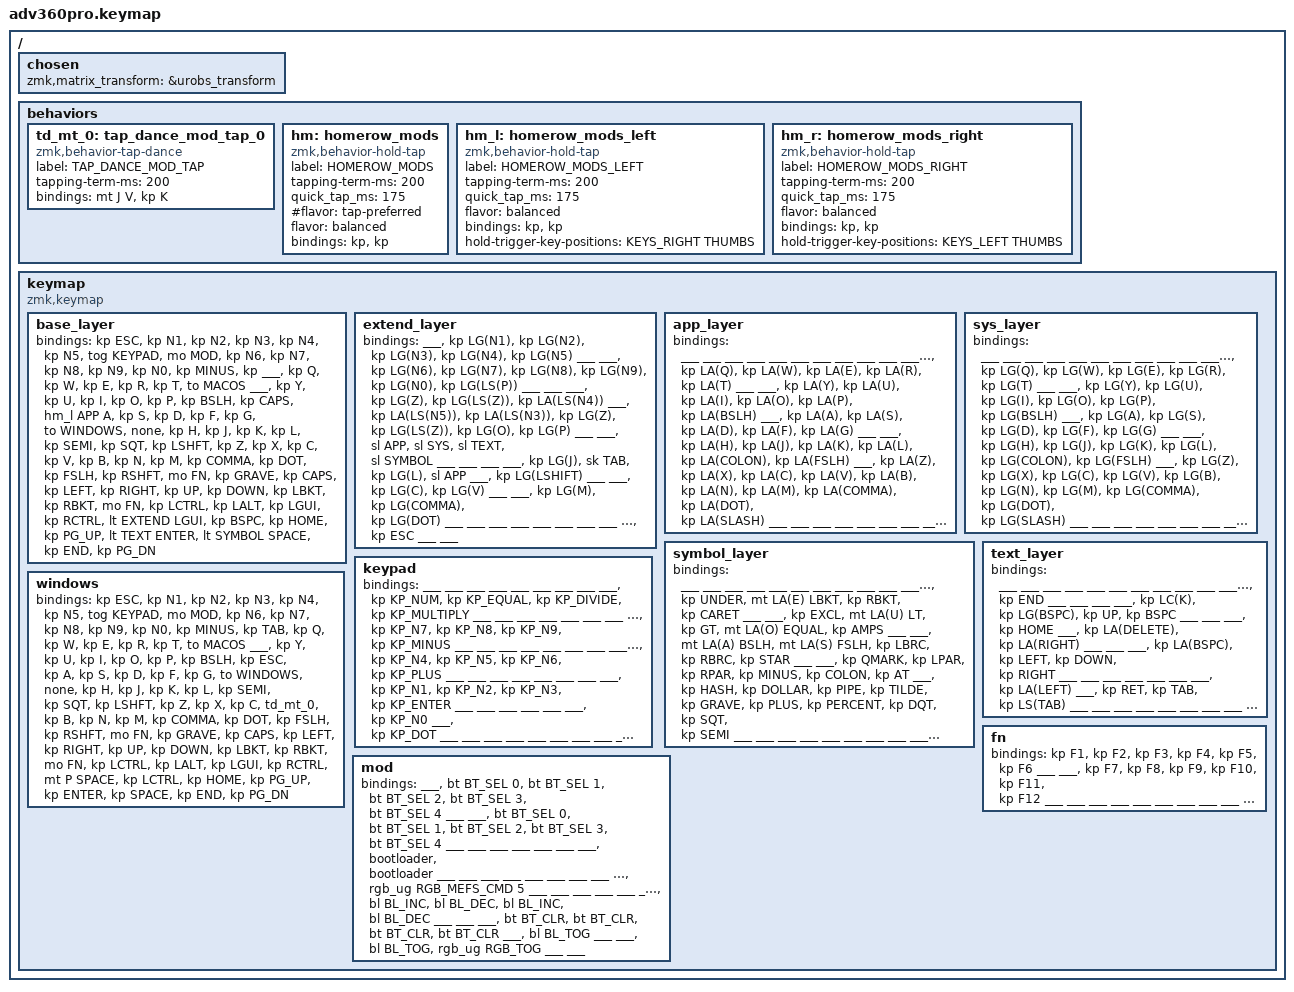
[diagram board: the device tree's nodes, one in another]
#include <behaviors.dtsi>
#include <dt-bindings/zmk/keys.h>
#include <dt-bindings/zmk/bt.h>
#include <dt-bindings/zmk/outputs.h>
#include <dt-bindings/zmk/rgb.h>
#include <dt-bindings/zmk/backlight.h>

#define ___ &trans

#define MACOS 0
#define EXTEND 1
#define APP 2
#define SYS 3
#define SYMBOL 4
#define TEXT 5
#define WINDOWS 6
#define KEYPAD 7
#define FN 8
#define MOD 9

/ {
    /* remove unused keys from layout and move thumb cluster to bottom */
    chosen {
        zmk,matrix_transform = &urobs_transform;
    };

    behaviors {
        td_mt_0: tap_dance_mod_tap_0 {
            compatible = "zmk,behavior-tap-dance";
            label = "TAP_DANCE_MOD_TAP";
            #binding-cells = <0>;
            tapping-term-ms = <200>;
            bindings = <&mt J V>, <&kp K>;
        };

	hm: homerow_mods {
        	compatible = "zmk,behavior-hold-tap";
        	label = "HOMEROW_MODS";
        	#binding-cells = <2>;
        	tapping-term-ms = <200>;
        	quick_tap_ms = <175>;
        	#flavor = "tap-preferred";
        	flavor = "balanced";
        	bindings = <&kp>, <&kp>;
    	};

	hm_l: homerow_mods_left {
        	compatible = "zmk,behavior-hold-tap";
        	label = "HOMEROW_MODS_LEFT";
        	#binding-cells = <2>;
        	tapping-term-ms = <200>;
        	quick_tap_ms = <175>;
        	flavor = "balanced";
        	bindings = <&kp>, <&kp>;
        	hold-trigger-key-positions = <KEYS_RIGHT THUMBS>;
    	};

    	hm_r: homerow_mods_right {
        	compatible = "zmk,behavior-hold-tap";
        	label = "HOMEROW_MODS_RIGHT";
        	#binding-cells = <2>;
        	tapping-term-ms = <200>;
        	quick_tap_ms = <175>;
        	flavor = "balanced";
        	bindings = <&kp>, <&kp>;
        	hold-trigger-key-positions = <KEYS_LEFT THUMBS>;
    	};
    };

    keymap {
	#include "macros.dtsi"

        compatible = "zmk,keymap";

        base_layer {
            bindings = <
                &kp ESC &kp N1    &kp N2    &kp N3    &kp N4    &kp N5    &tog KEYPAD    &mo MOD   &kp N6    &kp N7    &kp N8    &kp N9    &kp N0    &kp MINUS
                &kp ___ &kp Q     &kp W     &kp E     &kp R     &kp T     &to MACOS    ___       &kp Y     &kp U     &kp I     &kp O     &kp P     &kp BSLH
                &kp CAPS  &hm_l APP A     &kp S     &kp D     &kp F     &kp G     &to WINDOWS    &none     &kp H     &kp J     &kp K     &kp L     &kp SEMI  &kp SQT
                &kp LSHFT &kp Z     &kp X     &kp C     &kp V     &kp B                              &kp N     &kp M     &kp COMMA &kp DOT   &kp FSLH  &kp RSHFT
                &mo FN    &kp GRAVE &kp CAPS  &kp LEFT  &kp RIGHT                                              &kp UP    &kp DOWN  &kp LBKT  &kp RBKT  &mo FN
                                                                  &kp LCTRL &kp LALT       &kp LGUI  &kp RCTRL
                                                  &lt EXTEND LGUI &kp BSPC &kp HOME       &kp PG_UP &lt TEXT ENTER &lt SYMBOL SPACE
                                                                            &kp END        &kp PG_DN
            >;
        };

        extend_layer {
            bindings = <
                ___    &kp LG(N1)  &kp LG(N2)  &kp LG(N3)  &kp LG(N4)  &kp LG(N5)   ___            ___      &kp LG(N6)  &kp LG(N7)  &kp LG(N8)  &kp LG(N9)  &kp LG(N0)   &kp LG(LS(P)) 
                ___       ___       ___   &kp LG(Z) &kp LG(LS(Z))  &kp LA(LS(N4))       ___            &kp LA(LS(N5))  &kp LA(LS(N3))    &kp LG(Z) &kp LG(LS(Z))  &kp LG(O)     &kp LG(P)   ___
                ___       &sl APP   &sl SYS  &sl TEXT  &sl SYMBOL   ___       ___            ___       ___     &kp LG(J)     &sk TAB     &kp LG(L)     &sl APP    ___ 
                &kp LG(LSHIFT) ___     ___     &kp LG(C)     &kp LG(V)     ___                              ___     &kp LG(M)     &kp LG(COMMA) &kp LG(DOT)   ___  ___
                ___       ___       ___       ___       ___                                                    ___       ___       ___       ___       ___
                                                                  ___       ___            ___       ___
                                                        ___       ___       ___            ___       ___       &kp ESC
                                                                            ___            ___
            >;
        };

	app_layer {
            bindings = <
                ___       ___       ___       ___       ___       ___       ___            ___       ___       ___       ___       ___       ___       ___
                ___       &kp LA(Q)     &kp LA(W)    &kp LA(E)     &kp LA(R)     &kp LA(T)     ___            ___       &kp LA(Y)     &kp LA(U)     &kp LA(I)     &kp LA(O)     &kp LA(P)   &kp LA(BSLH)
                ___       &kp LA(A)     &kp LA(S)    &kp LA(D)     &kp LA(F)     &kp LA(G)     ___            ___       &kp LA(H)     &kp LA(J)     &kp LA(K)     &kp LA(L)     &kp LA(COLON)     &kp LA(FSLH)
                ___       &kp LA(Z)     &kp LA(X)     &kp LA(C)     &kp LA(V)     &kp LA(B)                             &kp LA(N)     &kp LA(M)    &kp LA(COMMA) &kp LA(DOT)   &kp LA(SLASH)  ___
                ___       ___       ___       ___       ___                                                    ___       ___       ___       ___       ___
                                                                  ___       ___            ___       ___
                                                        ___       ___       ___            ___       ___       ___
                                                                            ___            ___
            >;
        };

	sys_layer {
            bindings = <
                ___       ___       ___       ___       ___       ___       ___            ___       ___       ___       ___       ___       ___       ___
                ___       &kp LG(Q)     &kp LG(W)    &kp LG(E)     &kp LG(R)     &kp LG(T)     ___            ___       &kp LG(Y)     &kp LG(U)     &kp LG(I)     &kp LG(O)     &kp LG(P)   &kp LG(BSLH)
                ___       &kp LG(A)     &kp LG(S)    &kp LG(D)     &kp LG(F)     &kp LG(G)     ___            ___       &kp LG(H)     &kp LG(J)     &kp LG(K)     &kp LG(L)     &kp LG(COLON)     &kp LG(FSLH)
                ___       &kp LG(Z)     &kp LG(X)     &kp LG(C)     &kp LG(V)     &kp LG(B)                             &kp LG(N)     &kp LG(M)    &kp LG(COMMA) &kp LG(DOT)   &kp LG(SLASH)  ___
                ___       ___       ___       ___       ___                                                    ___       ___       ___       ___       ___
                                                                  ___       ___            ___       ___
                                                        ___       ___       ___            ___       ___       ___
                                                                            ___            ___
            >;
        };

	symbol_layer {
            bindings = <
                ___       ___       ___       ___       ___       ___       ___            ___       ___       ___       ___       ___       ___       ___
                ___       ___     &kp UNDER    &mt LA(E) LBKT     &kp RBKT     &kp CARET     ___            ___       &kp EXCL     &mt LA(U) LT     &kp GT     &mt LA(O) EQUAL     &kp AMPS   ___
                ___       &mt LA(A) BSLH     &mt LA(S) FSLH    &kp LBRC     &kp RBRC     &kp STAR     ___            ___       &kp QMARK     &kp LPAR     &kp RPAR     &kp MINUS     &kp COLON     &kp AT
                ___       &kp HASH     &kp DOLLAR     &kp PIPE     &kp TILDE     &kp GRAVE                             &kp PLUS     &kp PERCENT    &kp DQT &kp SQT   &kp SEMI  ___
                ___       ___       ___       ___       ___                                                    ___       ___       ___       ___       ___
                                                                  ___       ___            ___       ___
                                                        ___       ___       ___            ___       ___       ___
                                                                            ___            ___
            >;
        };

	text_layer {
            bindings = <
                ___       ___       ___       ___       ___       ___       ___            ___       ___        ___   ___       ___       ___       ___
                ___       ___       ___       &kp END   ___       ___       ___            ___       &kp LC(K)  &kp LG(BSPC)  &kp UP    &kp BSPC  ___       ___
                ___       &kp HOME  ___       &kp LA(DELETE)  &kp LA(RIGHT) ___       ___       ___       &kp LA(BSPC)  &kp LEFT  &kp DOWN  &kp RIGHT ___       ___
                ___       ___       ___       ___       ___       &kp LA(LEFT)             ___       &kp RET   &kp TAB   &kp LS(TAB)  ___    ___     ___
                ___       ___       ___       ___       ___                                                    ___       ___       ___       ___       ___
                                                                  ___       ___            ___       ___
                                                        ___       ___       ___            ___       ___       ___
                                                                            ___            ___
            >;
        };

	
	windows {
            bindings = <
                &kp ESC &kp N1    &kp N2    &kp N3    &kp N4    &kp N5    &tog KEYPAD    &mo MOD   &kp N6    &kp N7    &kp N8    &kp N9    &kp N0    &kp MINUS
                &kp TAB   &kp Q     &kp W     &kp E     &kp R     &kp T     &to MACOS    ___       &kp Y     &kp U     &kp I     &kp O     &kp P     &kp BSLH
                &kp ESC   &kp A     &kp S     &kp D     &kp F     &kp G     &to WINDOWS    &none     &kp H     &kp J     &kp K     &kp L     &kp SEMI  &kp SQT
                &kp LSHFT &kp Z     &kp X     &kp C     &td_mt_0  &kp B                              &kp N     &kp M     &kp COMMA &kp DOT   &kp FSLH  &kp RSHFT
                &mo FN    &kp GRAVE &kp CAPS  &kp LEFT  &kp RIGHT                                              &kp UP    &kp DOWN  &kp LBKT  &kp RBKT  &mo FN
                                                                  &kp LCTRL &kp LALT       &kp LGUI  &kp RCTRL
                                          &mt P SPACE &kp LCTRL &kp HOME       &kp PG_UP &kp ENTER &kp SPACE
                                                                            &kp END        &kp PG_DN
            >;
        };

        keypad {
            bindings = <
                ___       ___       ___       ___       ___       ___       ___            ___       ___       &kp KP_NUM &kp KP_EQUAL &kp KP_DIVIDE &kp KP_MULTIPLY ___
                ___       ___       ___       ___       ___       ___       ___            ___       ___       &kp KP_N7  &kp KP_N8    &kp KP_N9     &kp KP_MINUS    ___
                ___       ___       ___       ___       ___       ___       ___            ___       ___       &kp KP_N4  &kp KP_N5    &kp KP_N6     &kp KP_PLUS     ___
                ___       ___       ___       ___       ___       ___                                ___       &kp KP_N1  &kp KP_N2    &kp KP_N3     &kp KP_ENTER    ___
                ___       ___       ___       ___       ___                                                    &kp KP_N0  ___          &kp KP_DOT    ___             ___
                                                                  ___       ___            ___       ___
                                                        ___       ___       ___            ___       ___       ___
                                                                            ___            ___
            >;
        };

        fn {
            bindings = <
                &kp F1    &kp F2    &kp F3    &kp F4    &kp F5    &kp F6    ___            ___       &kp F7    &kp F8    &kp F9    &kp F10   &kp F11   &kp F12
                ___       ___       ___       ___       ___       ___       ___            ___       ___       ___       ___       ___       ___       ___
                ___       ___       ___       ___       ___       ___       ___            ___       ___       ___       ___       ___       ___       ___
                ___       ___       ___       ___       ___       ___                                ___       ___       ___       ___       ___       ___
                ___       ___       ___       ___       ___                                                    ___       ___       ___       ___       ___
                                                                  ___       ___            ___       ___
                                                        ___       ___       ___            ___       ___       ___
                                                                            ___            ___
            >;
        };

        mod {
            bindings = <
                ___       &bt BT_SEL 0 &bt BT_SEL 1 &bt BT_SEL 2 &bt BT_SEL 3 &bt BT_SEL 4 ___              ___         &bt BT_SEL 0 &bt BT_SEL 1     &bt BT_SEL 2 &bt BT_SEL 3 &bt BT_SEL 4 ___
                ___       ___          ___          ___          ___          ___          &bootloader      &bootloader ___          ___              ___          ___          ___          ___
                ___       ___          ___          ___          ___          ___          ___              &rgb_ug RGB_MEFS_CMD 5   ___          ___              ___          ___          ___          ___
                ___       ___          ___          ___          ___          ___                                       ___          ___              ___          ___          ___          ___
                ___       ___          ___          &bl BL_INC   &bl BL_DEC                                                          &bl BL_INC       &bl BL_DEC   ___          ___          ___
                                                                              &bt BT_CLR   &bt BT_CLR       &bt BT_CLR  &bt BT_CLR
                                                                 ___          &bl BL_TOG   ___              ___         &bl BL_TOG   &rgb_ug RGB_TOG
                                                                                           ___              ___
            >;
        };
    };

};

